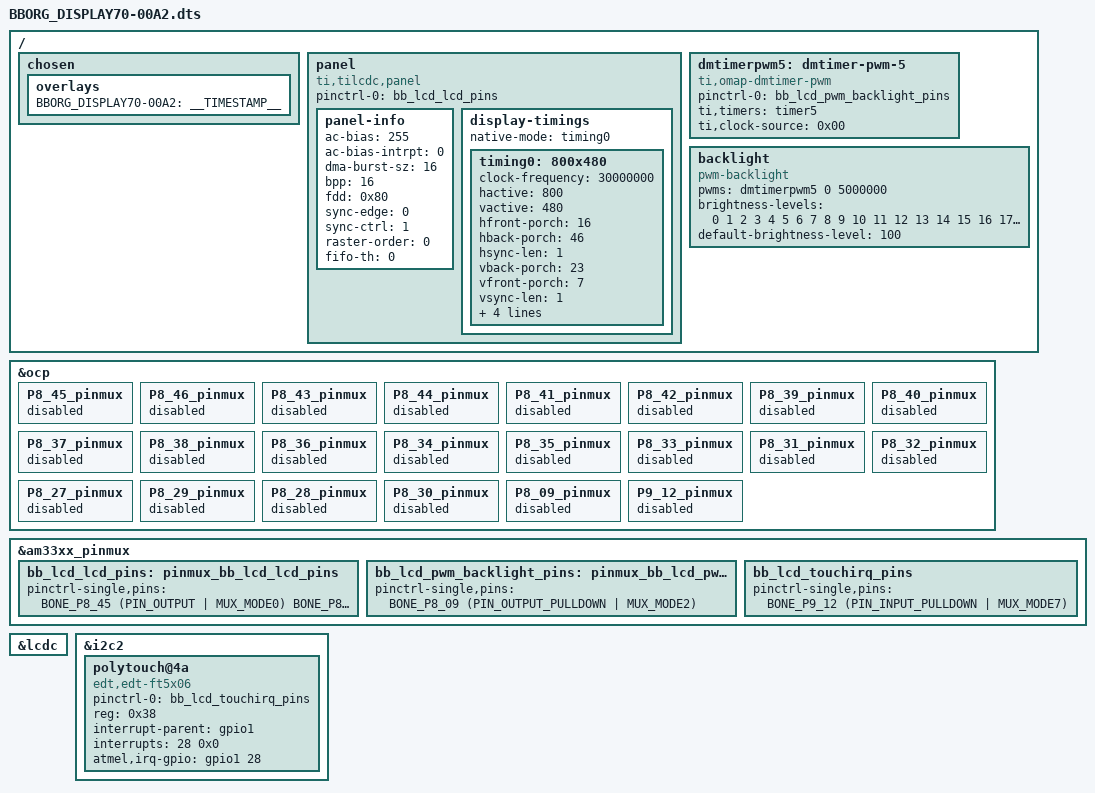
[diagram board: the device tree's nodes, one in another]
/*
 * Copyright (C) 2012 Texas Instruments Incorporated - http://www.ti.com/
 *
 * This program is free software; you can redistribute it and/or modify
 * it under the terms of the GNU General Public License version 2 as
 * published by the Free Software Foundation.
 */

/dts-v1/;
/plugin/;

#include <dt-bindings/gpio/gpio.h>
#include <dt-bindings/pinctrl/am33xx.h>
#include <dt-bindings/board/am335x-bbw-bbb-base.h>

/ {
	/*
	 * Helper to show loaded overlays under: /proc/device-tree/chosen/overlays/
	 */
	fragment@0 {
		target-path="/";
		__overlay__ {

			chosen {
				overlays {
					BBORG_DISPLAY70-00A2 = __TIMESTAMP__;
				};
			};
		};
	};

    /*
     * Free up the pins used by the cape from the pinmux helpers.
     */
    fragment@1 {
        target = <&ocp>;
        __overlay__ {

            P8_45_pinmux { status = "disabled"; };  /* P8_45: lcd_data0.lcd_data0 */
            P8_46_pinmux { status = "disabled"; };  /* P8_46: lcd_data1.lcd_data1 */
            P8_43_pinmux { status = "disabled"; };  /* P8_43: lcd_data2.lcd_data2 */
            P8_44_pinmux { status = "disabled"; };  /* P8_44: lcd_data3.lcd_data3 */
            P8_41_pinmux { status = "disabled"; };  /* P8_41: lcd_data4.lcd_data4 */
            P8_42_pinmux { status = "disabled"; };  /* P8_42: lcd_data5.lcd_data5 */
            P8_39_pinmux { status = "disabled"; };  /* P8_39: lcd_data6.lcd_data6 */
            P8_40_pinmux { status = "disabled"; };  /* P8_40: lcd_data7.lcd_data7 */
            P8_37_pinmux { status = "disabled"; };  /* P8_37: lcd_data8.lcd_data8 */
            P8_38_pinmux { status = "disabled"; };  /* P8_38: lcd_data9.lcd_data9 */
            P8_36_pinmux { status = "disabled"; };  /* P8_36: lcd_data10.lcd_data10 */
            P8_34_pinmux { status = "disabled"; };  /* P8_34: lcd_data11.lcd_data11 */
            P8_35_pinmux { status = "disabled"; };  /* P8_35: lcd_data12.lcd_data12 */
            P8_33_pinmux { status = "disabled"; };  /* P8_33: lcd_data13.lcd_data13 */
            P8_31_pinmux { status = "disabled"; };  /* P8_31: lcd_data14.lcd_data14 */
            P8_32_pinmux { status = "disabled"; };  /* P8_32: lcd_data15.lcd_data15 */

            P8_27_pinmux { status = "disabled"; };  /* P8_27: lcd_vsync.lcd_vsync */
            P8_29_pinmux { status = "disabled"; };  /* P8_29: lcd_hsync.lcd_hsync */
            P8_28_pinmux { status = "disabled"; };  /* P8_28: lcd_pclk.lcd_pclk */
            P8_30_pinmux { status = "disabled"; };  /* P8_30: lcd_ac_bias_en.lcd_ac_bias_en */

            P8_09_pinmux { status = "disabled"; };  /* P8_09: backlight: timer: gpmc_be0n_cle.timer5 (gpio69) */
            P9_12_pinmux { status = "disabled"; };  /* P9_12: touch irq: gpio: gpmc_ben1.gpio1_28 (gpio60) */
        };
    };

    fragment@2 {
        target = <&am33xx_pinmux>;
        __overlay__ {
            bb_lcd_lcd_pins: pinmux_bb_lcd_lcd_pins {
                pinctrl-single,pins = <
                    BONE_P8_45 (PIN_OUTPUT | MUX_MODE0) /* P8_45: lcd_data0.lcd_data0 */
                    BONE_P8_46 (PIN_OUTPUT | MUX_MODE0) /* P8_46: lcd_data1.lcd_data1 */
                    BONE_P8_43 (PIN_OUTPUT | MUX_MODE0) /* P8_43: lcd_data2.lcd_data2 */
                    BONE_P8_44 (PIN_OUTPUT | MUX_MODE0) /* P8_44: lcd_data3.lcd_data3 */
                    BONE_P8_41 (PIN_OUTPUT | MUX_MODE0) /* P8_41: lcd_data4.lcd_data4 */
                    BONE_P8_42 (PIN_OUTPUT | MUX_MODE0) /* P8_42: lcd_data5.lcd_data5 */
                    BONE_P8_39 (PIN_OUTPUT | MUX_MODE0) /* P8_39: lcd_data6.lcd_data6 */
                    BONE_P8_40 (PIN_OUTPUT | MUX_MODE0) /* P8_40: lcd_data7.lcd_data7 */
                    BONE_P8_37 (PIN_OUTPUT | MUX_MODE0) /* P8_37: lcd_data8.lcd_data8 */
                    BONE_P8_38 (PIN_OUTPUT | MUX_MODE0) /* P8_38: lcd_data9.lcd_data9 */
                    BONE_P8_36 (PIN_OUTPUT | MUX_MODE0) /* P8_36: lcd_data10.lcd_data10 */
                    BONE_P8_34 (PIN_OUTPUT | MUX_MODE0) /* P8_34: lcd_data11.lcd_data11 */
                    BONE_P8_35 (PIN_OUTPUT | MUX_MODE0) /* P8_35: lcd_data12.lcd_data12 */
                    BONE_P8_33 (PIN_OUTPUT | MUX_MODE0) /* P8_33: lcd_data13.lcd_data13 */
                    BONE_P8_31 (PIN_OUTPUT | MUX_MODE0) /* P8_31: lcd_data14.lcd_data14 */
                    BONE_P8_32 (PIN_OUTPUT | MUX_MODE0) /* P8_32: lcd_data15.lcd_data15 */

                    BONE_P8_27 (PIN_OUTPUT | MUX_MODE0) /* P8_27: lcd_vsync.lcd_vsync */
                    BONE_P8_29 (PIN_OUTPUT | MUX_MODE0) /* P8_29: lcd_hsync.lcd_hsync */
                    BONE_P8_28 (PIN_OUTPUT | MUX_MODE0) /* P8_28: lcd_pclk.lcd_pclk */
                    BONE_P8_30 (PIN_OUTPUT | MUX_MODE0) /* P8_30: lcd_ac_bias_en.lcd_ac_bias_en */
                >;
            };
            bb_lcd_pwm_backlight_pins: pinmux_bb_lcd_pwm_backlight_pins {
                pinctrl-single,pins = <
                    BONE_P8_09 (PIN_OUTPUT_PULLDOWN | MUX_MODE2) /* P8_09: backlight: timer: gpmc_be0n_cle.timer5 (gpio69) */
                >;
            };
        };
    };

    fragment@3 {
        target = <&lcdc>;
        __overlay__ {
            status = "okay";
        };
    };

    /* EastRising ER-TFT070-4 / LCD7 cape */
    fragment@4 {
        target-path="/";
        __overlay__ {
            panel {
                status = "okay";
                compatible = "ti,tilcdc,panel";
                pinctrl-names = "default";
                pinctrl-0 = <&bb_lcd_lcd_pins>;

                panel-info {
                    ac-bias           = <255>;
                    ac-bias-intrpt    = <0>;
                    dma-burst-sz      = <16>;
                    bpp               = <16>;
                    fdd               = <0x80>;
                    sync-edge         = <0>;
                    sync-ctrl         = <1>;
                    raster-order      = <0>;
                    fifo-th           = <0>;
                };
                display-timings {
                    native-mode = <&timing0>;
                    /* Settings for EastRising ER-TFT070-4 / LCD7 cape: */
                    timing0: 800x480 {
                        clock-frequency = <30000000>;
                        hactive = <800>;
                        vactive = <480>;
                        hfront-porch = <16>;
                        hback-porch = <46>;
                        hsync-len = <1>;
                        vback-porch = <23>;
                        vfront-porch = <7>;
                        vsync-len = <1>;
                        hsync-active = <0>;
                        vsync-active = <0>;
                        de-active = <1>;
                        pixelclk-active = <0>;
                    };
                };
            };
        };
    };

    /* LCD PWM BackLight */
    fragment@5 {
        target-path="/";
        __overlay__ {
            dmtimerpwm5: dmtimer-pwm-5 {
                status = "okay";
                compatible = "ti,omap-dmtimer-pwm";
                pinctrl-names = "default";
                pinctrl-0 = <&bb_lcd_pwm_backlight_pins>;

                #pwm-cells = <2>;
                ti,timers = <&timer5>;
                //ti,prescaler = <0>;       /* 0 thru 7 */
                ti,clock-source = <0x00>;   /* timer_sys_ck */
                //ti,clock-source = <0x01>; /* timer_32k_ck */
            };
        };
    };

    fragment@6 {
        target-path="/";
        __overlay__ {
            backlight {
                status = "okay";
                compatible = "pwm-backlight";
                pwms = <&dmtimerpwm5 0 5000000>;
                brightness-levels = <
                    0  1  2  3  4  5  6  7  8  9
                    10 11 12 13 14 15 16 17 18 19
                    20 21 22 23 24 25 26 27 28 29
                    30 31 32 33 34 35 36 37 38 39
                    40 41 42 43 44 45 46 47 48 49
                    50 51 52 53 54 55 56 57 58 59
                    60 61 62 63 64 65 66 67 68 69
                    70 71 72 73 74 75 76 77 78 79
                    80 81 82 83 84 85 86 87 88 89
                    90 91 92 93 94 95 96 97 98 99
                    100
                >;
                default-brightness-level = <100>;
            };
        };
    };

    fragment@7 {
        target = <&am33xx_pinmux>;
        __overlay__ {
            bb_lcd_touchirq_pins: bb_lcd_touchirq_pins {
                pinctrl-single,pins = <
                    BONE_P9_12 (PIN_INPUT_PULLDOWN | MUX_MODE7) /* P9_12: touch irq: gpio: gpmc_ben1.gpio1_28 (gpio60) */
                >;
            };
        };
    };

    /* ER-TPC070-6 Cap Touch Panel (Using FocalTech EDT-5316 Multitouch Controller) */
    fragment@8 {
        target = <&i2c2>;
        __overlay__ {
            /* needed to avoid gripping by DTC */
            #address-cells = <1>;
            #size-cells = <0>;

            polytouch@4a {
                status = "okay";
                compatible = "edt,edt-ft5x06";
                pinctrl-names = "default";
                pinctrl-0 = <&bb_lcd_touchirq_pins>;

                reg = <0x38>;
                interrupt-parent = <&gpio1>;
                interrupts = <28 0x0>;
                atmel,irq-gpio = <&gpio1 28 0>;
            };
        };
    };
};

